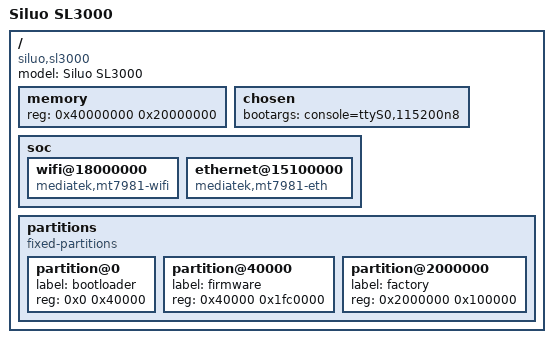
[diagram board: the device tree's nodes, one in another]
/dts-v1/;

/ {
    compatible = "siluo,sl3000", "mediatek,mt7981";
    model = "Siluo SL3000";

    memory {
        device_type = "memory";
        reg = <0x40000000 0x20000000>; /* 512MB */
    };

    chosen {
        bootargs = "console=ttyS0,115200n8";
    };

    soc {
        wifi@18000000 {
            compatible = "mediatek,mt7981-wifi";
            status = "okay";
        };

        ethernet@15100000 {
            compatible = "mediatek,mt7981-eth";
            status = "okay";
        };
    };

    partitions {
        compatible = "fixed-partitions";
        #address-cells = <1>;
        #size-cells = <1>;

        partition@0 {
            label = "bootloader";
            reg = <0x0 0x40000>;
        };

        partition@40000 {
            label = "firmware";
            reg = <0x40000 0x1fc0000>;
        };

        partition@2000000 {
            label = "factory";
            reg = <0x2000000 0x100000>;
        };
    };
};
